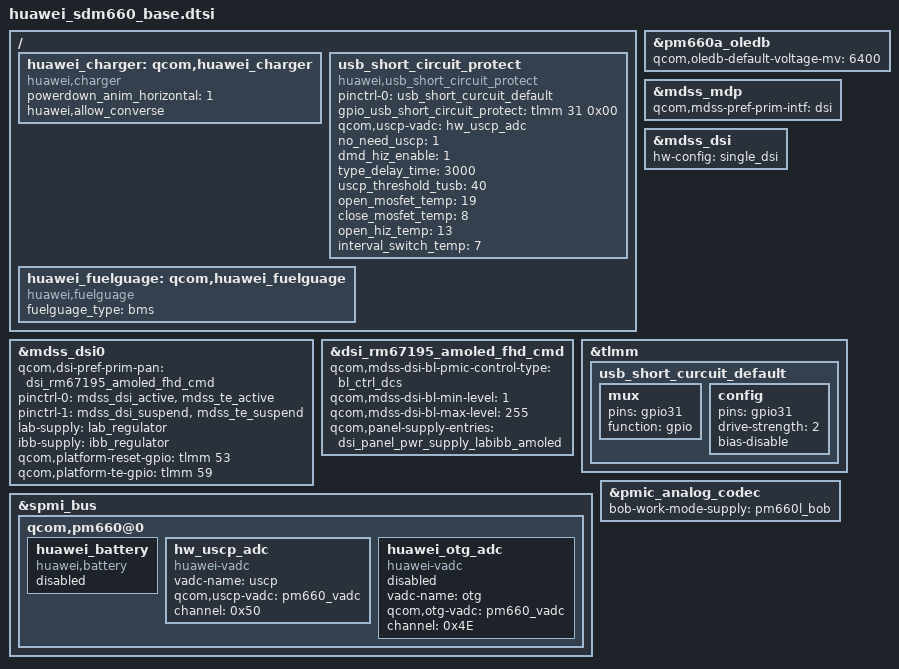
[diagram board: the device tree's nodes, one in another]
/*=============================================================================
                           Huawei Base Dtsi File
  GENERAL DESCRIPTION
    This file is for include the Communal node

  Copyright 2010-2014 by HUAWEI Technologies, Inc.  All Rights Reserved.
=============================================================================*/


#include "sdm660.dtsi"
#include "sdm660-qrd.dtsi"
#include "msm-pm660a.dtsi"
#include "sdm660-internal-codec.dtsi"

&pm660a_oledb {
	status = "okay";
	qcom,oledb-default-voltage-mv = <6400>;
};

&mdss_mdp {
	qcom,mdss-pref-prim-intf = "dsi";
};

&mdss_dsi {
	hw-config = "single_dsi";
};

&mdss_dsi0 {
	qcom,dsi-pref-prim-pan = <&dsi_rm67195_amoled_fhd_cmd>;
	pinctrl-names = "mdss_default", "mdss_sleep";
	pinctrl-0 = <&mdss_dsi_active &mdss_te_active>;
	pinctrl-1 = <&mdss_dsi_suspend &mdss_te_suspend>;
	lab-supply = <&lab_regulator>;
	ibb-supply = <&ibb_regulator>;
	qcom,platform-reset-gpio = <&tlmm 53 0>;
	qcom,platform-te-gpio = <&tlmm 59 0>;
};

&dsi_rm67195_amoled_fhd_cmd {
	qcom,mdss-dsi-bl-pmic-control-type = "bl_ctrl_dcs";
	qcom,mdss-dsi-bl-min-level = <1>;
	qcom,mdss-dsi-bl-max-level = <255>;
	qcom,panel-supply-entries = <&dsi_panel_pwr_supply_labibb_amoled>;
};
/{
    huawei_charger: qcom,huawei_charger{
        compatible = "huawei,charger";
        status = "okay";
        powerdown_anim_horizontal = "1";
		huawei,allow_converse;

    };
};
&tlmm {
	usb_short_curcuit_default: usb_short_curcuit_default {
			mux {
				pins = "gpio31";
				function =  "gpio";
			};
			config {
				pins = "gpio31";
				drive-strength = <2>;
				bias-disable;
		};
	};
};
/{
    usb_short_circuit_protect: usb_short_circuit_protect{
                compatible = "huawei,usb_short_circuit_protect";
		pinctrl-names = "default";
		pinctrl-0 = <&usb_short_curcuit_default>;
		gpio_usb_short_circuit_protect = <&tlmm 31 0x00>;
		qcom,uscp-vadc = <&hw_uscp_adc>;
                no_need_uscp = <1>;
		dmd_hiz_enable = <1>;
		type_delay_time = <3000>;
                uscp_threshold_tusb = <40>;
		open_mosfet_temp = <19>;
		close_mosfet_temp = <8>;
		open_hiz_temp = <13>;
		interval_switch_temp = <7>;
                status = "ok";
        };
};
/{
    huawei_fuelguage: qcom,huawei_fuelguage{
        compatible = "huawei,fuelguage";
        fuelguage_type = "bms";
        status = "okay";
    };
};
&spmi_bus {
	qcom,pm660@0 {

			huawei_battery: huawei_battery {
				compatible = "huawei,battery";
				status = "disabled";
		 };
    hw_uscp_adc: hw_uscp_adc {
        compatible="huawei-vadc";
        vadc-name="uscp";
        qcom,uscp-vadc=<&pm660_vadc>;
        channel = <0x50>;
        status="okay";
    };
    huawei_otg_adc: huawei_otg_adc {
        compatible="huawei-vadc";
        vadc-name="otg";
        qcom,otg-vadc=<&pm660_vadc>;
        channel = <0x4E>;
        status="disabled";
    };
	};
};

&pmic_analog_codec {
    bob-work-mode-supply = <&pm660l_bob>;
};
